AUTOSAR XML (schema 3.1.2)
package /Components/SWC_VSSp
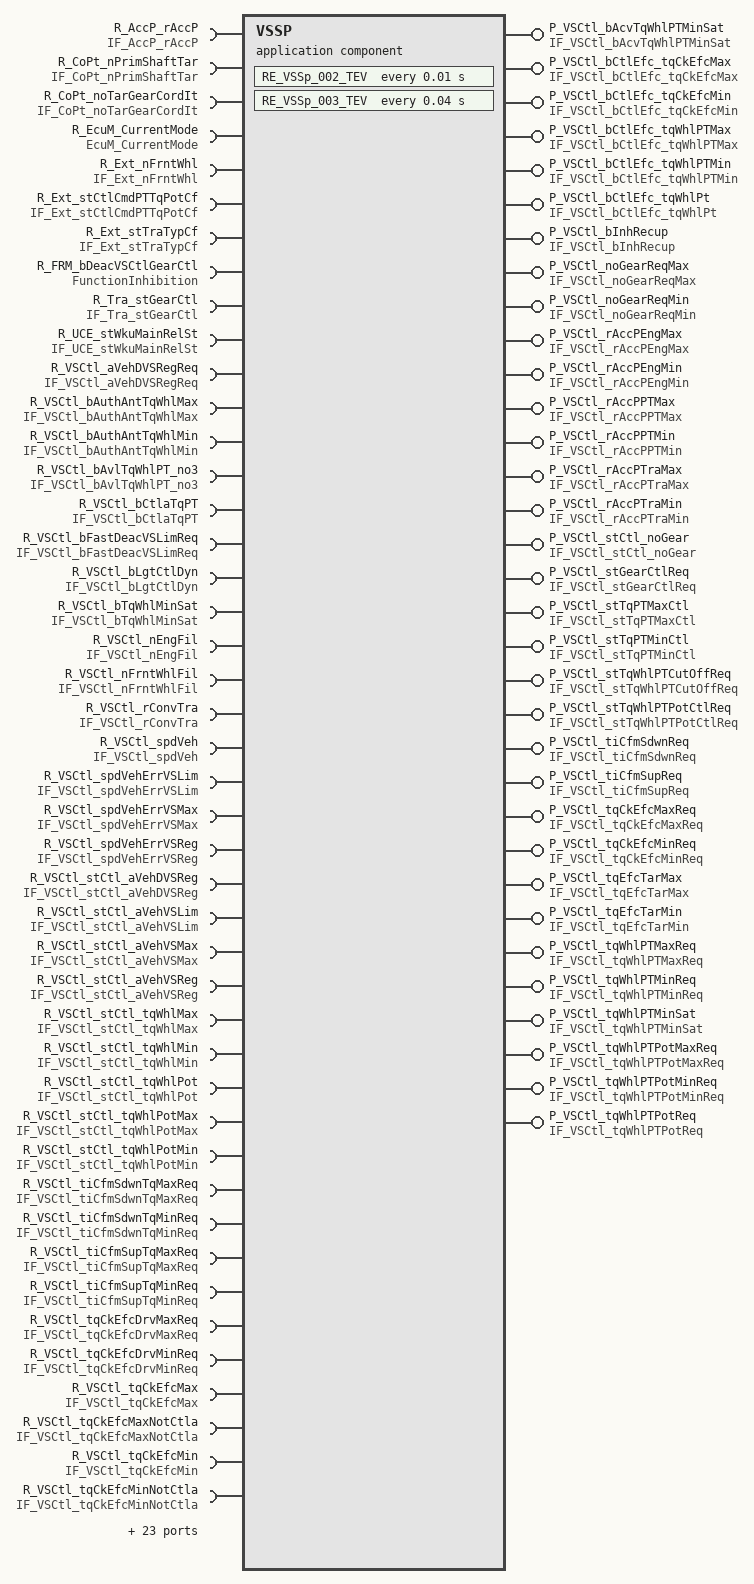
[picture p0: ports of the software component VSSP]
  application software component type VSSP  # VSSp
    33 x provide port:
      P_VSCtl_bAcvTqWhlPTMinSat: unqueued-sender-com-spec{data-element=VSCtl_bAcvTqWhlPTMinSat, can-invalidate=false, init-value=C_Boolean_False}, provided-interface=IF_VSCtl_bAcvTqWhlPTMinSat
      P_VSCtl_bCtlEfc_tqCkEfcMax: unqueued-sender-com-spec{data-element=VSCtl_bCtlEfc_tqCkEfcMax, can-invalidate=false, init-value=ConstantValue}, provided-interface=IF_VSCtl_bCtlEfc_tqCkEfcMax
      P_VSCtl_bCtlEfc_tqCkEfcMin: unqueued-sender-com-spec{data-element=VSCtl_bCtlEfc_tqCkEfcMin, can-invalidate=false, init-value=ConstantValue1}, provided-interface=IF_VSCtl_bCtlEfc_tqCkEfcMin
      P_VSCtl_bCtlEfc_tqWhlPTMax: unqueued-sender-com-spec{data-element=VSCtl_bCtlEfc_tqWhlPTMax, can-invalidate=false, init-value=ConstantValue3}, provided-interface=IF_VSCtl_bCtlEfc_tqWhlPTMax
      P_VSCtl_bCtlEfc_tqWhlPTMin: unqueued-sender-com-spec{data-element=VSCtl_bCtlEfc_tqWhlPTMin, can-invalidate=false, init-value=ConstantValue5}, provided-interface=IF_VSCtl_bCtlEfc_tqWhlPTMin
      P_VSCtl_bCtlEfc_tqWhlPt: unqueued-sender-com-spec{data-element=VSCtl_bCtlEfc_tqWhlPt, can-invalidate=false, init-value=C_Boolean_False7}, provided-interface=IF_VSCtl_bCtlEfc_tqWhlPt
      P_VSCtl_bInhRecup: unqueued-sender-com-spec{data-element=VSCtl_bInhRecup, can-invalidate=false, init-value=ConstantValue9}, provided-interface=IF_VSCtl_bInhRecup
      P_VSCtl_noGearReqMax: unqueued-sender-com-spec{data-element=VSCtl_noGearReqMax, can-invalidate=false, init-value=C_UInt8_15}, provided-interface=IF_VSCtl_noGearReqMax
      P_VSCtl_noGearReqMin: unqueued-sender-com-spec{data-element=VSCtl_noGearReqMin, can-invalidate=false, init-value=C_UInt8_0}, provided-interface=IF_VSCtl_noGearReqMin
      P_VSCtl_rAccPEngMax: unqueued-sender-com-spec{data-element=VSCtl_rAccPEngMax, can-invalidate=false, init-value=ConstantValue11}, provided-interface=IF_VSCtl_rAccPEngMax
      P_VSCtl_rAccPEngMin: unqueued-sender-com-spec{data-element=VSCtl_rAccPEngMin, can-invalidate=false, init-value=ConstantValue13}, provided-interface=IF_VSCtl_rAccPEngMin
      P_VSCtl_rAccPPTMax: unqueued-sender-com-spec{data-element=VSCtl_rAccPPTMax, can-invalidate=false, init-value=C_UInt16_12800}, provided-interface=IF_VSCtl_rAccPPTMax
      P_VSCtl_rAccPPTMin: unqueued-sender-com-spec{data-element=VSCtl_rAccPPTMin, can-invalidate=false, init-value=C_UInt16_0}, provided-interface=IF_VSCtl_rAccPPTMin
      P_VSCtl_rAccPTraMax: unqueued-sender-com-spec{data-element=VSCtl_rAccPTraMax, can-invalidate=false, init-value=ConstantValue15}, provided-interface=IF_VSCtl_rAccPTraMax
      P_VSCtl_rAccPTraMin: unqueued-sender-com-spec{data-element=VSCtl_rAccPTraMin, can-invalidate=false, init-value=ConstantValue17}, provided-interface=IF_VSCtl_rAccPTraMin
      P_VSCtl_stCtl_noGear: unqueued-sender-com-spec{data-element=VSCtl_stCtl_noGear, can-invalidate=false, init-value=ConstantValue19}, provided-interface=IF_VSCtl_stCtl_noGear
      P_VSCtl_stGearCtlReq: unqueued-sender-com-spec{data-element=VSCtl_stGearCtlReq, can-invalidate=false, init-value=C_UInt8_021}, provided-interface=IF_VSCtl_stGearCtlReq
      P_VSCtl_stTqPTMaxCtl: unqueued-sender-com-spec{data-element=VSCtl_stTqPTMaxCtl, can-invalidate=false, init-value=ConstantValue23}, provided-interface=IF_VSCtl_stTqPTMaxCtl
      P_VSCtl_stTqPTMinCtl: unqueued-sender-com-spec{data-element=VSCtl_stTqPTMinCtl, can-invalidate=false, init-value=ConstantValue25}, provided-interface=IF_VSCtl_stTqPTMinCtl
      P_VSCtl_stTqWhlPTCutOffReq: unqueued-sender-com-spec{data-element=VSCtl_stTqWhlPTCutOffReq, can-invalidate=false, init-value=ConstantValue27}, provided-interface=IF_VSCtl_stTqWhlPTCutOffReq
      P_VSCtl_stTqWhlPTPotCtlReq: unqueued-sender-com-spec{data-element=VSCtl_stTqWhlPTPotCtlReq, can-invalidate=false, init-value=C_UInt8_029}, provided-interface=IF_VSCtl_stTqWhlPTPotCtlReq
      P_VSCtl_tiCfmSdwnReq: unqueued-sender-com-spec{data-element=VSCtl_tiCfmSdwnReq, can-invalidate=false, init-value=C_UInt16_031}, provided-interface=IF_VSCtl_tiCfmSdwnReq
      P_VSCtl_tiCfmSupReq: unqueued-sender-com-spec{data-element=VSCtl_tiCfmSupReq, can-invalidate=false, init-value=C_UInt16_033}, provided-interface=IF_VSCtl_tiCfmSupReq
      P_VSCtl_tqCkEfcMaxReq: unqueued-sender-com-spec{data-element=VSCtl_tqCkEfcMaxReq, can-invalidate=false, init-value=ConstantValue35}, provided-interface=IF_VSCtl_tqCkEfcMaxReq
      P_VSCtl_tqCkEfcMinReq: unqueued-sender-com-spec{data-element=VSCtl_tqCkEfcMinReq, can-invalidate=false, init-value=ConstantValue37}, provided-interface=IF_VSCtl_tqCkEfcMinReq
      P_VSCtl_tqEfcTarMax: unqueued-sender-com-spec{data-element=VSCtl_tqEfcTarMax, can-invalidate=false, init-value=C_SInt16_32000}, provided-interface=IF_VSCtl_tqEfcTarMax
      P_VSCtl_tqEfcTarMin: unqueued-sender-com-spec{data-element=VSCtl_tqEfcTarMin, can-invalidate=false, init-value=C_SInt16_m32000}, provided-interface=IF_VSCtl_tqEfcTarMin
      P_VSCtl_tqWhlPTMaxReq: unqueued-sender-com-spec{data-element=VSCtl_tqWhlPTMaxReq, can-invalidate=false, init-value=C_SInt16_22000}, provided-interface=IF_VSCtl_tqWhlPTMaxReq
      P_VSCtl_tqWhlPTMinReq: unqueued-sender-com-spec{data-element=VSCtl_tqWhlPTMinReq, can-invalidate=false, init-value=C_SInt16_m8000}, provided-interface=IF_VSCtl_tqWhlPTMinReq
      P_VSCtl_tqWhlPTMinSat: unqueued-sender-com-spec{data-element=VSCtl_tqWhlPTMinSat, can-invalidate=false, init-value=C_SInt16_m800039}, provided-interface=IF_VSCtl_tqWhlPTMinSat
      P_VSCtl_tqWhlPTPotMaxReq: unqueued-sender-com-spec{data-element=VSCtl_tqWhlPTPotMaxReq, can-invalidate=false, init-value=C_SInt16_2200041}, provided-interface=IF_VSCtl_tqWhlPTPotMaxReq
      P_VSCtl_tqWhlPTPotMinReq: unqueued-sender-com-spec{data-element=VSCtl_tqWhlPTPotMinReq, can-invalidate=false, init-value=C_SInt16_m800043}, provided-interface=IF_VSCtl_tqWhlPTPotMinReq
      P_VSCtl_tqWhlPTPotReq: unqueued-sender-com-spec{data-element=VSCtl_tqWhlPTPotReq, can-invalidate=false, init-value=C_SInt16_m800045}, provided-interface=IF_VSCtl_tqWhlPTPotReq
    67 x require port:
      R_AccP_rAccP: unqueued-receiver-com-spec{data-element=AccP_rAccP, init-value=ConstantValue47, resync-time=0}, required-interface=IF_AccP_rAccP
      R_CoPt_nPrimShaftTar: unqueued-receiver-com-spec{data-element=CoPt_nPrimShaftTar, init-value=ConstantValue49, resync-time=0}, required-interface=IF_CoPt_nPrimShaftTar
      R_CoPt_noTarGearCordIt: unqueued-receiver-com-spec{data-element=CoPt_noTarGearCordIt, init-value=ConstantValue51, resync-time=0}, required-interface=IF_CoPt_noTarGearCordIt
      R_EcuM_CurrentMode: required-interface=EcuM_CurrentMode  # Requirement: 01552_09_00532-SSTG-C007(2)
      R_Ext_nFrntWhl: unqueued-receiver-com-spec{data-element=Ext_nFrntWhl, init-value=ConstantValue53, resync-time=0}, required-interface=IF_Ext_nFrntWhl
      R_Ext_stCtlCmdPTTqPotCf: unqueued-receiver-com-spec{data-element=Ext_stCtlCmdPTTqPotCf, init-value=ConstantValue55, resync-time=0}, required-interface=IF_Ext_stCtlCmdPTTqPotCf
      R_Ext_stTraTypCf: unqueued-receiver-com-spec{data-element=Ext_stTraTypCf, init-value=ConstantValue57, resync-time=0}, required-interface=IF_Ext_stTraTypCf
      R_FRM_bDeacVSCtlGearCtl: required-interface=FunctionInhibition
      R_Tra_stGearCtl: unqueued-receiver-com-spec{data-element=Tra_stGearCtl, init-value=C_UInt8_059, resync-time=0}, required-interface=IF_Tra_stGearCtl
      R_UCE_stWkuMainRelSt: required-interface=IF_UCE_stWkuMainRelSt  # Requirement: 01552_09_00532-SSTG-C011(1)
      R_VSCtl_aVehDVSRegReq: unqueued-receiver-com-spec{data-element=VSCtl_aVehDVSRegReq, init-value=ConstantValue61, resync-time=0}, required-interface=IF_VSCtl_aVehDVSRegReq
      R_VSCtl_bAuthAntTqWhlMax: unqueued-receiver-com-spec{data-element=VSCtl_bAuthAntTqWhlMax, init-value=ConstantValue63, resync-time=0}, required-interface=IF_VSCtl_bAuthAntTqWhlMax
      R_VSCtl_bAuthAntTqWhlMin: unqueued-receiver-com-spec{data-element=VSCtl_bAuthAntTqWhlMin, init-value=ConstantValue65, resync-time=0}, required-interface=IF_VSCtl_bAuthAntTqWhlMin
      R_VSCtl_bAvlTqWhlPT_no3: unqueued-receiver-com-spec{data-element=VSCtl_bAvlTqWhlPT_no3, init-value=ConstantValue67, resync-time=0}, required-interface=IF_VSCtl_bAvlTqWhlPT_no3
      R_VSCtl_bCtlaTqPT: unqueued-receiver-com-spec{data-element=VSCtl_bCtlaTqPT, init-value=ConstantValue69, resync-time=0}, required-interface=IF_VSCtl_bCtlaTqPT
      R_VSCtl_bFastDeacVSLimReq: unqueued-receiver-com-spec{data-element=VSCtl_bFastDeacVSLimReq, init-value=ConstantValue71, resync-time=0}, required-interface=IF_VSCtl_bFastDeacVSLimReq
      R_VSCtl_bLgtCtlDyn: unqueued-receiver-com-spec{data-element=VSCtl_bLgtCtlDyn, init-value=ConstantValue73, resync-time=0}, required-interface=IF_VSCtl_bLgtCtlDyn
      R_VSCtl_bTqWhlMinSat: unqueued-receiver-com-spec{data-element=VSCtl_bTqWhlMinSat, init-value=ConstantValue75, resync-time=0}, required-interface=IF_VSCtl_bTqWhlMinSat
      R_VSCtl_nEngFil: unqueued-receiver-com-spec{data-element=VSCtl_nEngFil, init-value=ConstantValue77, resync-time=0}, required-interface=IF_VSCtl_nEngFil
      R_VSCtl_nFrntWhlFil: unqueued-receiver-com-spec{data-element=VSCtl_nFrntWhlFil, init-value=ConstantValue79, resync-time=0}, required-interface=IF_VSCtl_nFrntWhlFil
      R_VSCtl_rConvTra: unqueued-receiver-com-spec{data-element=VSCtl_rConvTra, init-value=ConstantValue81, resync-time=0}, required-interface=IF_VSCtl_rConvTra
      R_VSCtl_spdVeh: unqueued-receiver-com-spec{data-element=VSCtl_spdVeh, init-value=ConstantValue83, resync-time=0}, required-interface=IF_VSCtl_spdVeh
      R_VSCtl_spdVehErrVSLim: unqueued-receiver-com-spec{data-element=VSCtl_spdVehErrVSLim, init-value=ConstantValue85, resync-time=0}, required-interface=IF_VSCtl_spdVehErrVSLim
      R_VSCtl_spdVehErrVSMax: unqueued-receiver-com-spec{data-element=VSCtl_spdVehErrVSMax, init-value=ConstantValue87, resync-time=0}, required-interface=IF_VSCtl_spdVehErrVSMax
      R_VSCtl_spdVehErrVSReg: unqueued-receiver-com-spec{data-element=VSCtl_spdVehErrVSReg, init-value=ConstantValue89, resync-time=0}, required-interface=IF_VSCtl_spdVehErrVSReg
      R_VSCtl_stCtl_aVehDVSReg: unqueued-receiver-com-spec{data-element=VSCtl_stCtl_aVehDVSReg, init-value=ConstantValue91, resync-time=0}, required-interface=IF_VSCtl_stCtl_aVehDVSReg
      R_VSCtl_stCtl_aVehVSLim: unqueued-receiver-com-spec{data-element=VSCtl_stCtl_aVehVSLim, init-value=ConstantValue93, resync-time=0}, required-interface=IF_VSCtl_stCtl_aVehVSLim
      R_VSCtl_stCtl_aVehVSMax: unqueued-receiver-com-spec{data-element=VSCtl_stCtl_aVehVSMax, init-value=ConstantValue95, resync-time=0}, required-interface=IF_VSCtl_stCtl_aVehVSMax
      R_VSCtl_stCtl_aVehVSReg: unqueued-receiver-com-spec{data-element=VSCtl_stCtl_aVehVSReg, init-value=ConstantValue97, resync-time=0}, required-interface=IF_VSCtl_stCtl_aVehVSReg
      R_VSCtl_stCtl_tqWhlMax: unqueued-receiver-com-spec{data-element=VSCtl_stCtl_tqWhlMax, init-value=ConstantValue99, resync-time=0}, required-interface=IF_VSCtl_stCtl_tqWhlMax
      R_VSCtl_stCtl_tqWhlMin: unqueued-receiver-com-spec{data-element=VSCtl_stCtl_tqWhlMin, init-value=ConstantValue101, resync-time=0}, required-interface=IF_VSCtl_stCtl_tqWhlMin
      R_VSCtl_stCtl_tqWhlPot: unqueued-receiver-com-spec{data-element=VSCtl_stCtl_tqWhlPot, init-value=ConstantValue103, resync-time=0}, required-interface=IF_VSCtl_stCtl_tqWhlPot
      R_VSCtl_stCtl_tqWhlPotMax: unqueued-receiver-com-spec{data-element=VSCtl_stCtl_tqWhlPotMax, init-value=ConstantValue105, resync-time=0}, required-interface=IF_VSCtl_stCtl_tqWhlPotMax
      R_VSCtl_stCtl_tqWhlPotMin: unqueued-receiver-com-spec{data-element=VSCtl_stCtl_tqWhlPotMin, init-value=ConstantValue107, resync-time=0}, required-interface=IF_VSCtl_stCtl_tqWhlPotMin
      R_VSCtl_tiCfmSdwnTqMaxReq: unqueued-receiver-com-spec{data-element=VSCtl_tiCfmSdwnTqMaxReq, init-value=ConstantValue109, resync-time=0}, required-interface=IF_VSCtl_tiCfmSdwnTqMaxReq
      R_VSCtl_tiCfmSdwnTqMinReq: unqueued-receiver-com-spec{data-element=VSCtl_tiCfmSdwnTqMinReq, init-value=ConstantValue111, resync-time=0}, required-interface=IF_VSCtl_tiCfmSdwnTqMinReq
      R_VSCtl_tiCfmSupTqMaxReq: unqueued-receiver-com-spec{data-element=VSCtl_tiCfmSupTqMaxReq, init-value=ConstantValue113, resync-time=0}, required-interface=IF_VSCtl_tiCfmSupTqMaxReq
      R_VSCtl_tiCfmSupTqMinReq: unqueued-receiver-com-spec{data-element=VSCtl_tiCfmSupTqMinReq, init-value=ConstantValue115, resync-time=0}, required-interface=IF_VSCtl_tiCfmSupTqMinReq
      R_VSCtl_tqCkEfcDrvMaxReq: unqueued-receiver-com-spec{data-element=VSCtl_tqCkEfcDrvMaxReq, init-value=ConstantValue117, resync-time=0}, required-interface=IF_VSCtl_tqCkEfcDrvMaxReq
      R_VSCtl_tqCkEfcDrvMinReq: unqueued-receiver-com-spec{data-element=VSCtl_tqCkEfcDrvMinReq, init-value=ConstantValue119, resync-time=0}, required-interface=IF_VSCtl_tqCkEfcDrvMinReq
      R_VSCtl_tqCkEfcMax: unqueued-receiver-com-spec{data-element=VSCtl_tqCkEfcMax, init-value=ConstantValue121, resync-time=0}, required-interface=IF_VSCtl_tqCkEfcMax
      R_VSCtl_tqCkEfcMaxNotCtla: unqueued-receiver-com-spec{data-element=VSCtl_tqCkEfcMaxNotCtla, init-value=ConstantValue123, resync-time=0}, required-interface=IF_VSCtl_tqCkEfcMaxNotCtla
      R_VSCtl_tqCkEfcMin: unqueued-receiver-com-spec{data-element=VSCtl_tqCkEfcMin, init-value=ConstantValue125, resync-time=0}, required-interface=IF_VSCtl_tqCkEfcMin
      R_VSCtl_tqCkEfcMinNotCtla: unqueued-receiver-com-spec{data-element=VSCtl_tqCkEfcMinNotCtla, init-value=ConstantValue127, resync-time=0}, required-interface=IF_VSCtl_tqCkEfcMinNotCtla
      R_VSCtl_tqCkEfcPreCoVSCMinReq: unqueued-receiver-com-spec{data-element=VSCtl_tqCkEfcPreCoVSCMinReq, init-value=ConstantValue129, resync-time=0}, required-interface=IF_VSCtl_tqCkEfcPreCoVSCMinReq
      R_VSCtl_tqCkEfcPreCoVSCtlReq: unqueued-receiver-com-spec{data-element=VSCtl_tqCkEfcPreCoVSCtlReq, init-value=ConstantValue131, resync-time=0}, required-interface=IF_VSCtl_tqCkEfcPreCoVSCtlReq
      R_VSCtl_tqLossTra: unqueued-receiver-com-spec{data-element=VSCtl_tqLossTra, init-value=ConstantValue133, resync-time=0}, required-interface=IF_VSCtl_tqLossTra
      R_VSCtl_tqWhlMaxReq: unqueued-receiver-com-spec{data-element=VSCtl_tqWhlMaxReq, init-value=ConstantValue135, resync-time=0}, required-interface=IF_VSCtl_tqWhlMaxReq
      R_VSCtl_tqWhlMinReq: unqueued-receiver-com-spec{data-element=VSCtl_tqWhlMinReq, init-value=ConstantValue137, resync-time=0}, required-interface=IF_VSCtl_tqWhlMinReq
      R_VSCtl_tqWhlMinSat: unqueued-receiver-com-spec{data-element=VSCtl_tqWhlMinSat, init-value=ConstantValue139, resync-time=0}, required-interface=IF_VSCtl_tqWhlMinSat
      R_VSCtl_tqWhlPTDrvMaxReq: unqueued-receiver-com-spec{data-element=VSCtl_tqWhlPTDrvMaxReq, init-value=ConstantValue141, resync-time=0}, required-interface=IF_VSCtl_tqWhlPTDrvMaxReq
      R_VSCtl_tqWhlPTDrvMinReq: unqueued-receiver-com-spec{data-element=VSCtl_tqWhlPTDrvMinReq, init-value=ConstantValue143, resync-time=0}, required-interface=IF_VSCtl_tqWhlPTDrvMinReq
      R_VSCtl_tqWhlPTDrvMinReqRaw: unqueued-receiver-com-spec{data-element=VSCtl_tqWhlPTDrvMinReqRaw, init-value=ConstantValue145, resync-time=0}, required-interface=IF_VSCtl_tqWhlPTDrvMinReqRaw
      R_VSCtl_tqWhlPTMax: unqueued-receiver-com-spec{data-element=VSCtl_tqWhlPTMax, init-value=ConstantValue147, resync-time=0}, required-interface=IF_VSCtl_tqWhlPTMax
      R_VSCtl_tqWhlPTMaxNotCtla: unqueued-receiver-com-spec{data-element=VSCtl_tqWhlPTMaxNotCtla, init-value=ConstantValue149, resync-time=0}, required-interface=IF_VSCtl_tqWhlPTMaxNotCtla
      R_VSCtl_tqWhlPTMin: unqueued-receiver-com-spec{data-element=VSCtl_tqWhlPTMin, init-value=ConstantValue151, resync-time=0}, required-interface=IF_VSCtl_tqWhlPTMin
      R_VSCtl_tqWhlPTMinNotCtla: unqueued-receiver-com-spec{data-element=VSCtl_tqWhlPTMinNotCtla, init-value=ConstantValue153, resync-time=0}, required-interface=IF_VSCtl_tqWhlPTMinNotCtla
      R_VSCtl_tqWhlPTPotRawMax: unqueued-receiver-com-spec{data-element=VSCtl_tqWhlPTPotRawMax, init-value=ConstantValue155, resync-time=0}, required-interface=IF_VSCtl_tqWhlPTPotRawMax
      R_VSCtl_tqWhlPTPotRawMin: unqueued-receiver-com-spec{data-element=VSCtl_tqWhlPTPotRawMin, init-value=ConstantValue157, resync-time=0}, required-interface=IF_VSCtl_tqWhlPTPotRawMin
      R_VSCtl_tqWhlPTPreCoVSCMaxReq: unqueued-receiver-com-spec{data-element=VSCtl_tqWhlPTPreCoVSCMaxReq, init-value=ConstantValue159, resync-time=0}, required-interface=IF_VSCtl_tqWhlPTPreCoVSCMaxReq
      R_VSCtl_tqWhlPTPreCoVSCMinReq: unqueued-receiver-com-spec{data-element=VSCtl_tqWhlPTPreCoVSCMinReq, init-value=ConstantValue161, resync-time=0}, required-interface=IF_VSCtl_tqWhlPTPreCoVSCMinReq
      R_VSCtl_tqWhlPTPreCoVSCtlReq: unqueued-receiver-com-spec{data-element=VSCtl_tqWhlPTPreCoVSCtlReq, init-value=ConstantValue163, resync-time=0}, required-interface=IF_VSCtl_tqWhlPTPreCoVSCtlReq
      R_VSCtl_tqWhlPotMaxReq: unqueued-receiver-com-spec{data-element=VSCtl_tqWhlPotMaxReq, init-value=ConstantValue165, resync-time=0}, required-interface=IF_VSCtl_tqWhlPotMaxReq
      R_VSCtl_tqWhlPotMinReq: unqueued-receiver-com-spec{data-element=VSCtl_tqWhlPotMinReq, init-value=ConstantValue167, resync-time=0}, required-interface=IF_VSCtl_tqWhlPotMinReq
      R_VSCtl_tqWhlPotReq: unqueued-receiver-com-spec{data-element=VSCtl_tqWhlPotReq, init-value=ConstantValue169, resync-time=0}, required-interface=IF_VSCtl_tqWhlPotReq
      R_VSSp_GetTimer_1ms_U32: required-interface=IF_CS_FRunTime_1MS_U32
      R_Ext_bCtlCmdPTTqCf: unqueued-receiver-com-spec{data-element=Ext_bCtlCmdPTTqCf, init-value=ConstantValue171, resync-time=0}, required-interface=IF_Ext_bCtlCmdPTTqCf  # R_Ext_bVSMaxpCf
  102 x constant specification:
    C_Boolean_False
      value:
        boolean literal C_Boolean_False: type=DT_VSCtl_bAcvTqWhlPTMinSat, value=false
    C_Boolean_False173
      value:
        boolean literal C_Boolean_False173: type=DT_VSCtl_bCtlEfc_tqWhlPT_pt1, value=false
    C_Boolean_False175
      value:
        boolean literal C_Boolean_False175: type=DT_VSCtl_bCtlEfc_tqWhlPT_pt2, value=false
    C_Boolean_False7
      value:
        boolean literal C_Boolean_False7: type=DT_VSCtl_bCtlEfc_tqWhlPt, value=false
    C_SInt16_22000
      value:
        integer literal C_SInt16_22000: type=DT_VSCtl_tqWhlPTMaxReq, value=22000
    C_SInt16_2200041
      value:
        integer literal C_SInt16_2200041: type=DT_VSCtl_tqWhlPTPotMaxReq, value=22000
    C_SInt16_32000
      value:
        integer literal C_SInt16_32000: type=DT_VSCtl_tqEfcTarMax, value=32000
    C_SInt16_m32000
      value:
        integer literal C_SInt16_m32000: type=DT_VSCtl_tqEfcTarMin, value=-32000
    C_SInt16_m8000
      value:
        integer literal C_SInt16_m8000: type=DT_VSCtl_tqWhlPTMinReq, value=-8000
    C_SInt16_m800039
      value:
        integer literal C_SInt16_m800039: type=DT_VSCtl_tqWhlPTMinSat, value=-8000
    C_SInt16_m800043
      value:
        integer literal C_SInt16_m800043: type=DT_VSCtl_tqWhlPTPotMinReq, value=-8000
    C_SInt16_m800045
      value:
        integer literal C_SInt16_m800045: type=DT_VSCtl_tqWhlPTPotReq, value=-8000
    C_UInt16_0
      value:
        integer literal C_UInt16_0: type=DT_VSCtl_rAccPPTMin, value=0
    C_UInt16_031
      value:
        integer literal C_UInt16_031: type=DT_VSCtl_tiCfmSdwnReq, value=0
    C_UInt16_033
      value:
        integer literal C_UInt16_033: type=DT_VSCtl_tiCfmSupReq, value=0
    C_UInt16_12800
      value:
        integer literal C_UInt16_12800: type=DT_VSCtl_rAccPPTMax, value=12800
    C_UInt8_0
      value:
        integer literal C_UInt8_0: type=DT_VSCtl_noGearReqMin, value=0
    C_UInt8_0177
      value:
        integer literal C_UInt8_0177: type=DT_VSCtl_stTqPTMaxCtl_pt2, value=0
    C_UInt8_0179
      value:
        integer literal C_UInt8_0179: type=DT_VSCtl_stTqPTMaxCtl_pt1, value=0
    C_UInt8_0181
      value:
        integer literal C_UInt8_0181: type=DT_VSCtl_stTqPTMinCtl_pt2, value=0
    C_UInt8_0183
      value:
        integer literal C_UInt8_0183: type=DT_VSCtl_stTqPTMinCtl_pt1, value=0
    C_UInt8_021
      value:
        integer literal C_UInt8_021: type=DT_VSCtl_stGearCtlReq, value=0
    C_UInt8_029
      value:
        integer literal C_UInt8_029: type=DT_VSCtl_stTqWhlPTPotCtlReq, value=0
    C_UInt8_059
      value:
        integer literal C_UInt8_059: type=DT_Tra_stGearCtl, value=0
    C_UInt8_15
      value:
        integer literal C_UInt8_15: type=DT_VSCtl_noGearReqMax, value=15
    ConstantValue
      value:
        boolean literal ConstantValue: type=DT_VSCtl_bCtlEfc_tqCkEfcMax, value=false
    ConstantValue1
      value:
        boolean literal ConstantValue1: type=DT_VSCtl_bCtlEfc_tqCkEfcMin, value=false
    ConstantValue101
      value:
        boolean literal ConstantValue101: type=DT_VSCtl_stCtl_tqWhlMin, value=false
    ConstantValue103
      value:
        boolean literal ConstantValue103: type=DT_VSCtl_stCtl_tqWhlPot, value=false
    ConstantValue105
      value:
        integer literal ConstantValue105: type=DT_VSCtl_stCtl_tqWhlPotMax, value=0
    ConstantValue107
      value:
        integer literal ConstantValue107: type=DT_VSCtl_stCtl_tqWhlPotMin, value=0
    ConstantValue109
      value:
        integer literal ConstantValue109: type=DT_VSCtl_tiCfmSdwnTqMaxReq, value=0
    ConstantValue11
      value:
        integer literal ConstantValue11: type=DT_VSCtl_rAccPEngMax, value=12800
    ConstantValue111
      value:
        integer literal ConstantValue111: type=DT_VSCtl_tiCfmSdwnTqMinReq, value=0
    ConstantValue113
      value:
        integer literal ConstantValue113: type=DT_VSCtl_tiCfmSupTqMaxReq, value=0
    ConstantValue115
      value:
        integer literal ConstantValue115: type=DT_VSCtl_tiCfmSupTqMinReq, value=0
    ConstantValue117
      value:
        integer literal ConstantValue117: type=DT_VSCtl_tqCkEfcDrvMaxReq, value=32000
    ConstantValue119
      value:
        integer literal ConstantValue119: type=DT_VSCtl_tqCkEfcDrvMinReq, value=-32000
    ConstantValue121
      value:
        integer literal ConstantValue121: type=DT_VSCtl_tqCkEfcMax, value=32000
    ConstantValue123
      value:
        integer literal ConstantValue123: type=DT_VSCtl_tqCkEfcMaxNotCtla, value=0
    ConstantValue125
      value:
        integer literal ConstantValue125: type=DT_VSCtl_tqCkEfcMin, value=-32000
    ConstantValue127
      value:
        integer literal ConstantValue127: type=DT_VSCtl_tqCkEfcMinNotCtla, value=0
    ConstantValue129
      value:
        integer literal ConstantValue129: type=DT_VSCtl_tqCkEfcPreCoVSCMinReq, value=-32000
    ConstantValue13
      value:
        integer literal ConstantValue13: type=DT_VSCtl_rAccPEngMin, value=0
    ConstantValue131
      value:
        integer literal ConstantValue131: type=DT_VSCtl_tqCkEfcPreCoVSCtlReq, value=4000
    ConstantValue133
      value:
        integer literal ConstantValue133: type=DT_VSCtl_tqLossTra, value=0
    ConstantValue135
      value:
        integer literal ConstantValue135: type=DT_VSCtl_tqWhlMaxReq, value=32000
    ConstantValue137
      value:
        integer literal ConstantValue137: type=DT_VSCtl_tqWhlMinReq, value=-32000
    ConstantValue139
      value:
        integer literal ConstantValue139: type=DT_VSCtl_tqWhlMinSat, value=-32000
    ConstantValue141
      value:
        integer literal ConstantValue141: type=DT_VSCtl_tqWhlPTDrvMaxReq, value=32000
    ConstantValue143
      value:
        integer literal ConstantValue143: type=DT_VSCtl_tqWhlPTDrvMinReq, value=0
    ConstantValue145
      value:
        integer literal ConstantValue145: type=DT_VSCtl_tqWhlPTDrvMinReqRaw, value=0
    ConstantValue147
      value:
        integer literal ConstantValue147: type=DT_VSCtl_tqWhlPTMax, value=0
    ConstantValue149
      value:
        integer literal ConstantValue149: type=DT_VSCtl_tqWhlPTMaxNotCtla, value=0
    ConstantValue15
      value:
        integer literal ConstantValue15: type=DT_VSCtl_rAccPTraMax, value=0
    ConstantValue151
      value:
        integer literal ConstantValue151: type=DT_VSCtl_tqWhlPTMin, value=0
    ConstantValue153
      value:
        integer literal ConstantValue153: type=DT_VSCtl_tqWhlPTMinNotCtla, value=0
    ConstantValue155
      value:
        integer literal ConstantValue155: type=DT_VSCtl_tqWhlPTPotRawMax, value=-32000
    ConstantValue157
      value:
        integer literal ConstantValue157: type=DT_VSCtl_tqWhlPTPotRawMin, value=-32000
    ConstantValue159
      value:
        integer literal ConstantValue159: type=DT_VSCtl_tqWhlPTPreCoVSCMaxReq, value=-32000
    ConstantValue161
      value:
        integer literal ConstantValue161: type=DT_VSCtl_tqWhlPTPreCoVSCMinReq, value=-32000
    ConstantValue163
      value:
        integer literal ConstantValue163: type=DT_VSCtl_tqWhlPTPreCoVSCtlReq, value=0
    ConstantValue165
      value:
        integer literal ConstantValue165: type=DT_VSCtl_tqWhlPotMaxReq, value=32000
    ConstantValue167
      value:
        integer literal ConstantValue167: type=DT_VSCtl_tqWhlPotMinReq, value=-32000
    ConstantValue169
      value:
        integer literal ConstantValue169: type=DT_VSCtl_tqWhlPotReq, value=-32000
    ConstantValue17
      value:
        integer literal ConstantValue17: type=DT_VSCtl_rAccPTraMin, value=0
    ConstantValue171
      value:
        boolean literal ConstantValue171: type=DT_Ext_bCtlCmdPTTqCf, value=false
    ConstantValue19
      value:
        integer literal ConstantValue19: type=DT_VSCtl_stCtl_noGear, value=0
    ConstantValue23
      value:
        integer literal ConstantValue23: type=DT_VSCtl_stTqPTMaxCtl, value=0
    ConstantValue25
      value:
        integer literal ConstantValue25: type=DT_VSCtl_stTqPTMinCtl, value=0
    ConstantValue27
      value:
        integer literal ConstantValue27: type=DT_VSCtl_stTqWhlPTCutOffReq, value=0
    ConstantValue3
      value:
        boolean literal ConstantValue3: type=DT_VSCtl_bCtlEfc_tqWhlPTMax, value=false
    ConstantValue35
      value:
        integer literal ConstantValue35: type=DT_VSCtl_tqCkEfcMaxReq, value=32000
    ConstantValue37
      value:
        integer literal ConstantValue37: type=DT_VSCtl_tqCkEfcMinReq, value=-32000
    ConstantValue47
      value:
        integer literal ConstantValue47: type=DT_AccP_rAccP, value=0
    ConstantValue49
      value:
        integer literal ConstantValue49: type=DT_CoPt_nPrimShaftTar, value=0
    ConstantValue5
      value:
        boolean literal ConstantValue5: type=DT_VSCtl_bCtlEfc_tqWhlPTMin, value=false
    ConstantValue51
      value:
        integer literal ConstantValue51: type=DT_CoPt_noTarGearCordIt, value=0
    ConstantValue53
      value:
        integer literal ConstantValue53: type=DT_Ext_nFrntWhl, value=0
    ConstantValue55
      value:
        integer literal ConstantValue55: type=DT_Ext_stCtlCmdPTTqPotCf, value=0
    ConstantValue57
      value:
        integer literal ConstantValue57: type=DT_Ext_stTraTypCf, value=0
    ConstantValue61
      value:
        integer literal ConstantValue61: type=DT_VSCtl_aVehDVSRegReq, value=-10240
    ConstantValue63
      value:
        boolean literal ConstantValue63: type=DT_VSCtl_bAuthAntTqWhlMax, value=false
    ConstantValue65
      value:
        boolean literal ConstantValue65: type=DT_VSCtl_bAuthAntTqWhlMin, value=false
    ConstantValue67
      value:
        boolean literal ConstantValue67: type=DT_VSCtl_bAvlTqWhlPT_no3, value=false
    ConstantValue69
      value:
        boolean literal ConstantValue69: type=DT_VSCtl_bCtlaTqPT, value=false
    ConstantValue71
      value:
        boolean literal ConstantValue71: type=DT_VSCtl_bFastDeacVSLimReq, value=false
    ConstantValue73
      value:
        boolean literal ConstantValue73: type=DT_VSCtl_bLgtCtlDyn, value=false
    ConstantValue75
      value:
        boolean literal ConstantValue75: type=DT_VSCtl_bTqWhlMinSat, value=false
    ConstantValue77
      value:
        integer literal ConstantValue77: type=DT_VSCtl_nEngFil, value=0
    ConstantValue79
      value:
        integer literal ConstantValue79: type=DT_VSCtl_nFrntWhlFil, value=0
    ConstantValue81
      value:
        integer literal ConstantValue81: type=DT_VSCtl_rConvTra, value=2560
    ConstantValue83
      value:
        integer literal ConstantValue83: type=DT_VSCtl_spdVeh, value=0
    ConstantValue85
      value:
        integer literal ConstantValue85: type=DT_VSCtl_spdVehErrVSLim, value=0
    ConstantValue87
      value:
        integer literal ConstantValue87: type=DT_VSCtl_spdVehErrVSMax, value=0
    ConstantValue89
      value:
        integer literal ConstantValue89: type=DT_VSCtl_spdVehErrVSReg, value=0
    ConstantValue9
      value:
        boolean literal ConstantValue9: type=DT_VSCtl_bInhRecup, value=false
    ConstantValue91
      value:
        boolean literal ConstantValue91: type=DT_VSCtl_stCtl_aVehDVSReg, value=false
    ConstantValue93
      value:
        integer literal ConstantValue93: type=DT_VSCtl_stCtl_aVehVSLim, value=0
    ConstantValue95
      value:
        integer literal ConstantValue95: type=DT_VSCtl_stCtl_aVehVSMax, value=0
    ConstantValue97
      value:
        integer literal ConstantValue97: type=DT_VSCtl_stCtl_aVehVSReg, value=0
    ConstantValue99
      value:
        boolean literal ConstantValue99: type=DT_VSCtl_stCtl_tqWhlMax, value=false
  internal behavior IB_VSSp: component=VSSP
    mode switch event EV_VSSp_004_MSE: start-on-event=RE_VSSp_004_MSE, activation=ENTRY, mode=R_EcuM_CurrentMode.currentMode.RUN
    mode switch event EV_VSSp_001_MSE: start-on-event=RE_VSSp_001_MSE, activation=ENTRY, mode=R_EcuM_CurrentMode.currentMode.RUN
    timing event EV_VSSp_002_TEV: mode-dependency=dependent-on-mode=[R_UCE_stWkuMainRelSt.RCD_stWkuMainRelSt.Invalid, R_UCE_stWkuMainRelSt.RCD_stWkuMainRelSt.PostMainWakeUp, R_UCE_stWkuMainRelSt.RCD_stWkuMainRelSt.PreMainWakeUp], start-on-event=RE_VSSp_002_TEV, period=0.01
    timing event EV_VSSp_003_TEV: mode-dependency=dependent-on-mode=[R_UCE_stWkuMainRelSt.RCD_stWkuMainRelSt.Invalid, R_UCE_stWkuMainRelSt.RCD_stWkuMainRelSt.PostMainWakeUp, R_UCE_stWkuMainRelSt.RCD_stWkuMainRelSt.PreMainWakeUp], start-on-event=RE_VSSp_003_TEV, period=0.04
    6 x inter runnable variable, all with sw-calibration-access=READ-WRITE, communication-approach=EXPLICIT:
      VSCtl_bCtlEfc_tqWhlPT_pt2: type=DT_VSCtl_bCtlEfc_tqWhlPT_pt2, init-value=C_Boolean_False175
      VSCtl_stTqPTMaxCtl_pt2: type=DT_VSCtl_stTqPTMaxCtl_pt2, init-value=C_UInt8_0177
      VSCtl_bCtlEfc_tqWhlPT_pt1: type=DT_VSCtl_bCtlEfc_tqWhlPT_pt1, init-value=C_Boolean_False173
      VSCtl_stTqPTMinCtl_pt1: type=DT_VSCtl_stTqPTMinCtl_pt1, init-value=C_UInt8_0183
      VSCtl_stTqPTMinCtl_pt2: type=DT_VSCtl_stTqPTMinCtl_pt2, init-value=C_UInt8_0181
      VSCtl_stTqPTMaxCtl_pt1: type=DT_VSCtl_stTqPTMaxCtl_pt1, init-value=C_UInt8_0179
    4 x runnable:
      RE_VSSp_002_TEV: written-variable=[VSCtl_bCtlEfc_tqWhlPT_pt1, VSCtl_bCtlEfc_tqWhlPT_pt2, VSCtl_stTqPTMinCtl_pt1, VSCtl_stTqPTMinCtl_pt2, VSCtl_stTqPTMaxCtl_pt1, VSCtl_stTqPTMaxCtl_pt2]  # RE_01552_10_02851_10ms
        63 x data receive point:
          dr_VSCtl_tqWhlPTMin: data-element=R_VSCtl_tqWhlPTMin.VSCtl_tqWhlPTMin
          dr_VSCtl_tqCkEfcMin: data-element=R_VSCtl_tqCkEfcMin.VSCtl_tqCkEfcMin
          dr_VSCtl_tqWhlPTPotRawMax: data-element=R_VSCtl_tqWhlPTPotRawMax.VSCtl_tqWhlPTPotRawMax
          dr_VSCtl_tqWhlPTPreCoVSCMaxReq: data-element=R_VSCtl_tqWhlPTPreCoVSCMaxReq.VSCtl_tqWhlPTPreCoVSCMaxReq
          dr_VSCtl_bCtlaTqPT: data-element=R_VSCtl_bCtlaTqPT.VSCtl_bCtlaTqPT
          dr_VSCtl_spdVehErrVSMax: data-element=R_VSCtl_spdVehErrVSMax.VSCtl_spdVehErrVSMax
          dr_VSCtl_tqWhlPTDrvMinReqRaw: data-element=R_VSCtl_tqWhlPTDrvMinReqRaw.VSCtl_tqWhlPTDrvMinReqRaw
          dr_VSCtl_rConvTra: data-element=R_VSCtl_rConvTra.VSCtl_rConvTra
          dr_VSCtl_aVehDVSRegReq: data-element=R_VSCtl_aVehDVSRegReq.VSCtl_aVehDVSRegReq
          dr_VSCtl_tqCkEfcMax: data-element=R_VSCtl_tqCkEfcMax.VSCtl_tqCkEfcMax
          dr_VSCtl_stCtl_tqWhlMin: data-element=R_VSCtl_stCtl_tqWhlMin.VSCtl_stCtl_tqWhlMin
          dr_AccP_rAccP: data-element=R_AccP_rAccP.AccP_rAccP
          dr_VSCtl_tqCkEfcDrvMaxReq: data-element=R_VSCtl_tqCkEfcDrvMaxReq.VSCtl_tqCkEfcDrvMaxReq
          dr_Ext_nFrntWhl: data-element=R_Ext_nFrntWhl.Ext_nFrntWhl
          dr_CoPt_nPrimShaftTar: data-element=R_CoPt_nPrimShaftTar.CoPt_nPrimShaftTar
          dr_VSCtl_tqWhlMaxReq: data-element=R_VSCtl_tqWhlMaxReq.VSCtl_tqWhlMaxReq
          dr_VSCtl_tqCkEfcPreCoVSCtlReq: data-element=R_VSCtl_tqCkEfcPreCoVSCtlReq.VSCtl_tqCkEfcPreCoVSCtlReq
          dr_Ext_stCtlCmdPTTqPotCf: data-element=R_Ext_stCtlCmdPTTqPotCf.Ext_stCtlCmdPTTqPotCf
          dr_VSCtl_tqWhlMinReq: data-element=R_VSCtl_tqWhlMinReq.VSCtl_tqWhlMinReq
          dr_Ext_stTraTypCf: data-element=R_Ext_stTraTypCf.Ext_stTraTypCf
          dr_VSCtl_tqCkEfcDrvMinReq: data-element=R_VSCtl_tqCkEfcDrvMinReq.VSCtl_tqCkEfcDrvMinReq
          dr_VSCtl_tqCkEfcMinNotCtla: data-element=R_VSCtl_tqCkEfcMinNotCtla.VSCtl_tqCkEfcMinNotCtla
          dr_VSCtl_bLgtCtlDyn: data-element=R_VSCtl_bLgtCtlDyn.VSCtl_bLgtCtlDyn
          dr_VSCtl_tqWhlPTPreCoVSCMinReq: data-element=R_VSCtl_tqWhlPTPreCoVSCMinReq.VSCtl_tqWhlPTPreCoVSCMinReq
          dr_VSCtl_nFrntWhlFil: data-element=R_VSCtl_nFrntWhlFil.VSCtl_nFrntWhlFil
          dr_VSCtl_tqWhlPTPreCoVSCtlReq: data-element=R_VSCtl_tqWhlPTPreCoVSCtlReq.VSCtl_tqWhlPTPreCoVSCtlReq
          dr_VSCtl_bAuthAntTqWhlMin: data-element=R_VSCtl_bAuthAntTqWhlMin.VSCtl_bAuthAntTqWhlMin
          dr_VSCtl_spdVeh: data-element=R_VSCtl_spdVeh.VSCtl_spdVeh
          dr_VSCtl_tqCkEfcPreCoVSCMinReq: data-element=R_VSCtl_tqCkEfcPreCoVSCMinReq.VSCtl_tqCkEfcPreCoVSCMinReq
          dr_VSCtl_tiCfmSdwnTqMinReq: data-element=R_VSCtl_tiCfmSdwnTqMinReq.VSCtl_tiCfmSdwnTqMinReq
          dr_VSCtl_bFastDeacVSLimReq: data-element=R_VSCtl_bFastDeacVSLimReq.VSCtl_bFastDeacVSLimReq
          dr_VSCtl_bAuthAntTqWhlMax: data-element=R_VSCtl_bAuthAntTqWhlMax.VSCtl_bAuthAntTqWhlMax
          dr_VSCtl_tqWhlPTPotRawMin: data-element=R_VSCtl_tqWhlPTPotRawMin.VSCtl_tqWhlPTPotRawMin
          dr_VSCtl_stCtl_aVehVSReg: data-element=R_VSCtl_stCtl_aVehVSReg.VSCtl_stCtl_aVehVSReg
          dr_VSCtl_stCtl_tqWhlPotMax: data-element=R_VSCtl_stCtl_tqWhlPotMax.VSCtl_stCtl_tqWhlPotMax
          dr_VSCtl_nEngFil: data-element=R_VSCtl_nEngFil.VSCtl_nEngFil
          dr_Tra_stGearCtl: data-element=R_Tra_stGearCtl.Tra_stGearCtl
          dr_VSCtl_tiCfmSdwnTqMaxReq: data-element=R_VSCtl_tiCfmSdwnTqMaxReq.VSCtl_tiCfmSdwnTqMaxReq
          dr_VSCtl_tqWhlPTMinNotCtla: data-element=R_VSCtl_tqWhlPTMinNotCtla.VSCtl_tqWhlPTMinNotCtla
          dr_VSCtl_stCtl_aVehVSLim: data-element=R_VSCtl_stCtl_aVehVSLim.VSCtl_stCtl_aVehVSLim
          dr_VSCtl_bTqWhlMinSat: data-element=R_VSCtl_bTqWhlMinSat.VSCtl_bTqWhlMinSat
          dr_VSCtl_tiCfmSupTqMinReq: data-element=R_VSCtl_tiCfmSupTqMinReq.VSCtl_tiCfmSupTqMinReq
          dr_VSCtl_stCtl_tqWhlMax: data-element=R_VSCtl_stCtl_tqWhlMax.VSCtl_stCtl_tqWhlMax
          dr_VSCtl_tqLossTra: data-element=R_VSCtl_tqLossTra.VSCtl_tqLossTra
          DRP_R_Ext_bCtlCmdPTTqCf_Ext_bCtlCmdPTTqCf: data-element=R_Ext_bCtlCmdPTTqCf.Ext_bCtlCmdPTTqCf
          dr_VSCtl_spdVehErrVSLim: data-element=R_VSCtl_spdVehErrVSLim.VSCtl_spdVehErrVSLim
          dr_VSCtl_stCtl_aVehDVSReg: data-element=R_VSCtl_stCtl_aVehDVSReg.VSCtl_stCtl_aVehDVSReg
          dr_VSCtl_bAvlTqWhlPT_no3: data-element=R_VSCtl_bAvlTqWhlPT_no3.VSCtl_bAvlTqWhlPT_no3
          dr_VSCtl_stCtl_tqWhlPot: data-element=R_VSCtl_stCtl_tqWhlPot.VSCtl_stCtl_tqWhlPot
          dr_VSCtl_tqWhlPotMaxReq: data-element=R_VSCtl_tqWhlPotMaxReq.VSCtl_tqWhlPotMaxReq
          dr_CoPt_noTarGearCordIt: data-element=R_CoPt_noTarGearCordIt.CoPt_noTarGearCordIt
          dr_VSCtl_tiCfmSupTqMaxReq: data-element=R_VSCtl_tiCfmSupTqMaxReq.VSCtl_tiCfmSupTqMaxReq
          dr_VSCtl_tqWhlPotReq: data-element=R_VSCtl_tqWhlPotReq.VSCtl_tqWhlPotReq
          dr_VSCtl_tqWhlPTDrvMinReq: data-element=R_VSCtl_tqWhlPTDrvMinReq.VSCtl_tqWhlPTDrvMinReq
          dr_VSCtl_tqWhlPTMaxNotCtla: data-element=R_VSCtl_tqWhlPTMaxNotCtla.VSCtl_tqWhlPTMaxNotCtla
          dr_VSCtl_tqWhlPTDrvMaxReq: data-element=R_VSCtl_tqWhlPTDrvMaxReq.VSCtl_tqWhlPTDrvMaxReq
          dr_VSCtl_tqWhlPTMax: data-element=R_VSCtl_tqWhlPTMax.VSCtl_tqWhlPTMax
          dr_VSCtl_tqWhlPotMinReq: data-element=R_VSCtl_tqWhlPotMinReq.VSCtl_tqWhlPotMinReq
          dr_VSCtl_spdVehErrVSReg: data-element=R_VSCtl_spdVehErrVSReg.VSCtl_spdVehErrVSReg
          dr_VSCtl_stCtl_aVehVSMax: data-element=R_VSCtl_stCtl_aVehVSMax.VSCtl_stCtl_aVehVSMax
          dr_VSCtl_tqCkEfcMaxNotCtla: data-element=R_VSCtl_tqCkEfcMaxNotCtla.VSCtl_tqCkEfcMaxNotCtla
          dr_VSCtl_stCtl_tqWhlPotMin: data-element=R_VSCtl_stCtl_tqWhlPotMin.VSCtl_stCtl_tqWhlPotMin
          dr_VSCtl_tqWhlMinSat: data-element=R_VSCtl_tqWhlMinSat.VSCtl_tqWhlMinSat
        30 x data send point:
          ds_VSCtl_noGearReqMax: data-element=P_VSCtl_noGearReqMax.VSCtl_noGearReqMax
          ds_VSCtl_bCtlEfc_tqCkEfcMin: data-element=P_VSCtl_bCtlEfc_tqCkEfcMin.VSCtl_bCtlEfc_tqCkEfcMin
          ds_VSCtl_bAcvTqWhlPTMinSat: data-element=P_VSCtl_bAcvTqWhlPTMinSat.VSCtl_bAcvTqWhlPTMinSat
          ds_VSCtl_stGearCtlReq: data-element=P_VSCtl_stGearCtlReq.VSCtl_stGearCtlReq
          ds_VSCtl_tqWhlPTMinReq: data-element=P_VSCtl_tqWhlPTMinReq.VSCtl_tqWhlPTMinReq
          ds_VSCtl_rAccPEngMax: data-element=P_VSCtl_rAccPEngMax.VSCtl_rAccPEngMax
          ds_VSCtl_tqEfcTarMin: data-element=P_VSCtl_tqEfcTarMin.VSCtl_tqEfcTarMin
          ds_VSCtl_stTqWhlPTCutOffReq: data-element=P_VSCtl_stTqWhlPTCutOffReq.VSCtl_stTqWhlPTCutOffReq
          ds_VSCtl_bCtlEfc_tqWhlPTMax: data-element=P_VSCtl_bCtlEfc_tqWhlPTMax.VSCtl_bCtlEfc_tqWhlPTMax
          ds_VSCtl_tqCkEfcMinReq: data-element=P_VSCtl_tqCkEfcMinReq.VSCtl_tqCkEfcMinReq
          ds_VSCtl_tqWhlPTPotMinReq: data-element=P_VSCtl_tqWhlPTPotMinReq.VSCtl_tqWhlPTPotMinReq
          ds_VSCtl_tqWhlPTMaxReq: data-element=P_VSCtl_tqWhlPTMaxReq.VSCtl_tqWhlPTMaxReq
          ds_VSCtl_bCtlEfc_tqCkEfcMax: data-element=P_VSCtl_bCtlEfc_tqCkEfcMax.VSCtl_bCtlEfc_tqCkEfcMax
          ds_VSCtl_tiCfmSupReq: data-element=P_VSCtl_tiCfmSupReq.VSCtl_tiCfmSupReq
          ds_VSCtl_rAccPPTMin: data-element=P_VSCtl_rAccPPTMin.VSCtl_rAccPPTMin
          ds_VSCtl_bCtlEfc_tqWhlPTMin: data-element=P_VSCtl_bCtlEfc_tqWhlPTMin.VSCtl_bCtlEfc_tqWhlPTMin
          ds_VSCtl_noGearReqMin: data-element=P_VSCtl_noGearReqMin.VSCtl_noGearReqMin
          ds_VSCtl_rAccPEngMin: data-element=P_VSCtl_rAccPEngMin.VSCtl_rAccPEngMin
          ds_VSCtl_tqCkEfcMaxReq: data-element=P_VSCtl_tqCkEfcMaxReq.VSCtl_tqCkEfcMaxReq
          ds_VSCtl_tqEfcTarMax: data-element=P_VSCtl_tqEfcTarMax.VSCtl_tqEfcTarMax
          ds_VSCtl_tqWhlPTPotReq: data-element=P_VSCtl_tqWhlPTPotReq.VSCtl_tqWhlPTPotReq
          ds_VSCtl_stCtl_noGear: data-element=P_VSCtl_stCtl_noGear.VSCtl_stCtl_noGear
          ds_VSCtl_rAccPPTMax: data-element=P_VSCtl_rAccPPTMax.VSCtl_rAccPPTMax
          ds_VSCtl_rAccPTraMin: data-element=P_VSCtl_rAccPTraMin.VSCtl_rAccPTraMin
          ds_VSCtl_tqWhlPTPotMaxReq: data-element=P_VSCtl_tqWhlPTPotMaxReq.VSCtl_tqWhlPTPotMaxReq
          ds_VSCtl_bInhRecup: data-element=P_VSCtl_bInhRecup.VSCtl_bInhRecup
          ds_VSCtl_tiCfmSdwnReq: data-element=P_VSCtl_tiCfmSdwnReq.VSCtl_tiCfmSdwnReq
          ds_VSCtl_tqWhlPTMinSat: data-element=P_VSCtl_tqWhlPTMinSat.VSCtl_tqWhlPTMinSat
          ds_VSCtl_stTqWhlPTPotCtlReq: data-element=P_VSCtl_stTqWhlPTPotCtlReq.VSCtl_stTqWhlPTPotCtlReq
          ds_VSCtl_rAccPTraMax: data-element=P_VSCtl_rAccPTraMax.VSCtl_rAccPTraMax
        sync call ssp_FRM_bDeacVSCtlGearCtl: operation=R_FRM_bDeacVSCtlGearCtl.GetFunctionPermission
        sync call ssp_GetTimer_1ms_U32: operation=R_VSSp_GetTimer_1ms_U32.GetTimer_1ms_U32
      RE_VSSp_003_TEV: read-variable=[VSCtl_stTqPTMaxCtl_pt1, VSCtl_bCtlEfc_tqWhlPT_pt2, VSCtl_bCtlEfc_tqWhlPT_pt1, VSCtl_stTqPTMinCtl_pt1, VSCtl_stTqPTMinCtl_pt2, VSCtl_stTqPTMaxCtl_pt2]  # RE_01552_10_02851_40ms
        data receive point DRP_R_Ext_bCtlCmdPTTqCf_Ext_bCtlCmdPTTqCf: data-element=R_Ext_bCtlCmdPTTqCf.Ext_bCtlCmdPTTqCf
        data send point ds_VSCtl_stTqPTMaxCtl: data-element=P_VSCtl_stTqPTMaxCtl.VSCtl_stTqPTMaxCtl
        data send point ds_VSCtl_stTqPTMinCtl: data-element=P_VSCtl_stTqPTMinCtl.VSCtl_stTqPTMinCtl
        data send point ds_VSCtl_bCtlEfc_tqWhlPt: data-element=P_VSCtl_bCtlEfc_tqWhlPt.VSCtl_bCtlEfc_tqWhlPt
        sync call ssp_GetTimer_1ms_U32: operation=R_VSSp_GetTimer_1ms_U32.GetTimer_1ms_U32
      RE_VSSp_004_MSE: written-variable=[VSCtl_bCtlEfc_tqWhlPT_pt1, VSCtl_stTqPTMaxCtl_pt2, VSCtl_stTqPTMinCtl_pt1, VSCtl_bCtlEfc_tqWhlPT_pt2, VSCtl_stTqPTMaxCtl_pt1, VSCtl_stTqPTMinCtl_pt2]  # RE_01552_10_02851_HotReset_init
        33 x data send point:
          ds_VSCtl_stTqWhlPTCutOffReq: data-element=P_VSCtl_stTqWhlPTCutOffReq.VSCtl_stTqWhlPTCutOffReq
          ds_VSCtl_stCtl_noGear: data-element=P_VSCtl_stCtl_noGear.VSCtl_stCtl_noGear
          ds_VSCtl_bCtlEfc_tqCkEfcMax: data-element=P_VSCtl_bCtlEfc_tqCkEfcMax.VSCtl_bCtlEfc_tqCkEfcMax
          ds_VSCtl_tqWhlPTPotReq: data-element=P_VSCtl_tqWhlPTPotReq.VSCtl_tqWhlPTPotReq
          ds_VSCtl_rAccPPTMin: data-element=P_VSCtl_rAccPPTMin.VSCtl_rAccPPTMin
          ds_VSCtl_stTqWhlPTPotCtlReq: data-element=P_VSCtl_stTqWhlPTPotCtlReq.VSCtl_stTqWhlPTPotCtlReq
          ds_VSCtl_tqWhlPTMinReq: data-element=P_VSCtl_tqWhlPTMinReq.VSCtl_tqWhlPTMinReq
          ds_VSCtl_tqWhlPTPotMaxReq: data-element=P_VSCtl_tqWhlPTPotMaxReq.VSCtl_tqWhlPTPotMaxReq
          ds_VSCtl_rAccPEngMin: data-element=P_VSCtl_rAccPEngMin.VSCtl_rAccPEngMin
          ds_VSCtl_stGearCtlReq: data-element=P_VSCtl_stGearCtlReq.VSCtl_stGearCtlReq
          ds_VSCtl_rAccPPTMax: data-element=P_VSCtl_rAccPPTMax.VSCtl_rAccPPTMax
          ds_VSCtl_bCtlEfc_tqWhlPt: data-element=P_VSCtl_bCtlEfc_tqWhlPt.VSCtl_bCtlEfc_tqWhlPt
          ds_VSCtl_bCtlEfc_tqWhlPTMin: data-element=P_VSCtl_bCtlEfc_tqWhlPTMin.VSCtl_bCtlEfc_tqWhlPTMin
          ds_VSCtl_rAccPTraMin: data-element=P_VSCtl_rAccPTraMin.VSCtl_rAccPTraMin
          ds_VSCtl_tqCkEfcMinReq: data-element=P_VSCtl_tqCkEfcMinReq.VSCtl_tqCkEfcMinReq
          ds_VSCtl_tqEfcTarMin: data-element=P_VSCtl_tqEfcTarMin.VSCtl_tqEfcTarMin
          ds_VSCtl_stTqPTMaxCtl: data-element=P_VSCtl_stTqPTMaxCtl.VSCtl_stTqPTMaxCtl
          ds_VSCtl_tqWhlPTPotMinReq: data-element=P_VSCtl_tqWhlPTPotMinReq.VSCtl_tqWhlPTPotMinReq
          ds_VSCtl_bCtlEfc_tqWhlPTMax: data-element=P_VSCtl_bCtlEfc_tqWhlPTMax.VSCtl_bCtlEfc_tqWhlPTMax
          ds_VSCtl_noGearReqMin: data-element=P_VSCtl_noGearReqMin.VSCtl_noGearReqMin
          ds_VSCtl_tqWhlPTMinSat: data-element=P_VSCtl_tqWhlPTMinSat.VSCtl_tqWhlPTMinSat
          ds_VSCtl_tiCfmSupReq: data-element=P_VSCtl_tiCfmSupReq.VSCtl_tiCfmSupReq
          ds_VSCtl_stTqPTMinCtl: data-element=P_VSCtl_stTqPTMinCtl.VSCtl_stTqPTMinCtl
          ds_VSCtl_bAcvTqWhlPTMinSat: data-element=P_VSCtl_bAcvTqWhlPTMinSat.VSCtl_bAcvTqWhlPTMinSat
          ds_VSCtl_tqWhlPTMaxReq: data-element=P_VSCtl_tqWhlPTMaxReq.VSCtl_tqWhlPTMaxReq
          ds_VSCtl_rAccPEngMax: data-element=P_VSCtl_rAccPEngMax.VSCtl_rAccPEngMax
          ds_VSCtl_rAccPTraMax: data-element=P_VSCtl_rAccPTraMax.VSCtl_rAccPTraMax
          ds_VSCtl_tqEfcTarMax: data-element=P_VSCtl_tqEfcTarMax.VSCtl_tqEfcTarMax
          ds_VSCtl_noGearReqMax: data-element=P_VSCtl_noGearReqMax.VSCtl_noGearReqMax
          ds_VSCtl_bCtlEfc_tqCkEfcMin: data-element=P_VSCtl_bCtlEfc_tqCkEfcMin.VSCtl_bCtlEfc_tqCkEfcMin
          ds_VSCtl_tiCfmSdwnReq: data-element=P_VSCtl_tiCfmSdwnReq.VSCtl_tiCfmSdwnReq
          ds_VSCtl_bInhRecup: data-element=P_VSCtl_bInhRecup.VSCtl_bInhRecup
          ds_VSCtl_tqCkEfcMaxReq: data-element=P_VSCtl_tqCkEfcMaxReq.VSCtl_tqCkEfcMaxReq
        sync call ssp_GetTimer_1ms_U32: operation=R_VSSp_GetTimer_1ms_U32.GetTimer_1ms_U32
      RE_VSSp_001_MSE: written-variable=[VSCtl_bCtlEfc_tqWhlPT_pt1, VSCtl_stTqPTMaxCtl_pt1, VSCtl_stTqPTMaxCtl_pt2, VSCtl_bCtlEfc_tqWhlPT_pt2, VSCtl_stTqPTMinCtl_pt1, VSCtl_stTqPTMinCtl_pt2]  # RE_01552_10_02851_init
        33 x data send point:
          ds_VSCtl_stCtl_noGear: data-element=P_VSCtl_stCtl_noGear.VSCtl_stCtl_noGear
          ds_VSCtl_tqWhlPTPotMaxReq: data-element=P_VSCtl_tqWhlPTPotMaxReq.VSCtl_tqWhlPTPotMaxReq
          ds_VSCtl_rAccPTraMax: data-element=P_VSCtl_rAccPTraMax.VSCtl_rAccPTraMax
          ds_VSCtl_rAccPEngMax: data-element=P_VSCtl_rAccPEngMax.VSCtl_rAccPEngMax
          ds_VSCtl_stTqPTMaxCtl: data-element=P_VSCtl_stTqPTMaxCtl.VSCtl_stTqPTMaxCtl
          ds_VSCtl_bCtlEfc_tqWhlPTMax: data-element=P_VSCtl_bCtlEfc_tqWhlPTMax.VSCtl_bCtlEfc_tqWhlPTMax
          ds_VSCtl_tqWhlPTMaxReq: data-element=P_VSCtl_tqWhlPTMaxReq.VSCtl_tqWhlPTMaxReq
          ds_VSCtl_tqWhlPTPotReq: data-element=P_VSCtl_tqWhlPTPotReq.VSCtl_tqWhlPTPotReq
          ds_VSCtl_tqEfcTarMax: data-element=P_VSCtl_tqEfcTarMax.VSCtl_tqEfcTarMax
          ds_VSCtl_tqCkEfcMaxReq: data-element=P_VSCtl_tqCkEfcMaxReq.VSCtl_tqCkEfcMaxReq
          ds_VSCtl_tqEfcTarMin: data-element=P_VSCtl_tqEfcTarMin.VSCtl_tqEfcTarMin
          ds_VSCtl_rAccPPTMax: data-element=P_VSCtl_rAccPPTMax.VSCtl_rAccPPTMax
          ds_VSCtl_tqCkEfcMinReq: data-element=P_VSCtl_tqCkEfcMinReq.VSCtl_tqCkEfcMinReq
          ds_VSCtl_stTqPTMinCtl: data-element=P_VSCtl_stTqPTMinCtl.VSCtl_stTqPTMinCtl
          ds_VSCtl_rAccPEngMin: data-element=P_VSCtl_rAccPEngMin.VSCtl_rAccPEngMin
          ds_VSCtl_rAccPTraMin: data-element=P_VSCtl_rAccPTraMin.VSCtl_rAccPTraMin
          ds_VSCtl_tiCfmSupReq: data-element=P_VSCtl_tiCfmSupReq.VSCtl_tiCfmSupReq
          ds_VSCtl_tqWhlPTMinReq: data-element=P_VSCtl_tqWhlPTMinReq.VSCtl_tqWhlPTMinReq
          ds_VSCtl_bInhRecup: data-element=P_VSCtl_bInhRecup.VSCtl_bInhRecup
          ds_VSCtl_stGearCtlReq: data-element=P_VSCtl_stGearCtlReq.VSCtl_stGearCtlReq
          ds_VSCtl_bCtlEfc_tqWhlPTMin: data-element=P_VSCtl_bCtlEfc_tqWhlPTMin.VSCtl_bCtlEfc_tqWhlPTMin
          ds_VSCtl_stTqWhlPTPotCtlReq: data-element=P_VSCtl_stTqWhlPTPotCtlReq.VSCtl_stTqWhlPTPotCtlReq
          ds_VSCtl_rAccPPTMin: data-element=P_VSCtl_rAccPPTMin.VSCtl_rAccPPTMin
          ds_VSCtl_bCtlEfc_tqCkEfcMax: data-element=P_VSCtl_bCtlEfc_tqCkEfcMax.VSCtl_bCtlEfc_tqCkEfcMax
          ds_VSCtl_bCtlEfc_tqWhlPt: data-element=P_VSCtl_bCtlEfc_tqWhlPt.VSCtl_bCtlEfc_tqWhlPt
          ds_VSCtl_noGearReqMax: data-element=P_VSCtl_noGearReqMax.VSCtl_noGearReqMax
          ds_VSCtl_bCtlEfc_tqCkEfcMin: data-element=P_VSCtl_bCtlEfc_tqCkEfcMin.VSCtl_bCtlEfc_tqCkEfcMin
          ds_VSCtl_noGearReqMin: data-element=P_VSCtl_noGearReqMin.VSCtl_noGearReqMin
          ds_VSCtl_bAcvTqWhlPTMinSat: data-element=P_VSCtl_bAcvTqWhlPTMinSat.VSCtl_bAcvTqWhlPTMinSat
          ds_VSCtl_tiCfmSdwnReq: data-element=P_VSCtl_tiCfmSdwnReq.VSCtl_tiCfmSdwnReq
          ds_VSCtl_stTqWhlPTCutOffReq: data-element=P_VSCtl_stTqWhlPTCutOffReq.VSCtl_stTqWhlPTCutOffReq
          ds_VSCtl_tqWhlPTMinSat: data-element=P_VSCtl_tqWhlPTMinSat.VSCtl_tqWhlPTMinSat
          ds_VSCtl_tqWhlPTPotMinReq: data-element=P_VSCtl_tqWhlPTPotMinReq.VSCtl_tqWhlPTPotMinReq
        sync call ssp_GetTimer_1ms_U32: operation=R_VSSp_GetTimer_1ms_U32.GetTimer_1ms_U32
  swc implementation Imp_VSSp: programming-language=C, behavior=IB_VSSp
    code-descriptors:
      code CodeDescriptor: type=SRC
        13 x xfile:
          VSSP_Control_Wheel_Gmp1_Sl_c: url=VSSP_Control_Wheel_Gmp1_Sl.c
          VSSP_Potential_Gmp_Sl_c: url=VSSP_Potential_Gmp_Sl.c
          VSSp_h: url=VSSp.h
          VSSP_Control_Wheel_Gmp2_Sl_c: url=VSSP_Control_Wheel_Gmp2_Sl.c
          VSSP_Position_Pedale_Sl_c: url=VSSP_Position_Pedale_Sl.c
          VSSP_Det_Gearbox_Speed_Sl_c: url=VSSP_Det_Gearbox_Speed_Sl.c
          VSSP_Torque_Control_Gmp1_Sf_c: url=VSSP_Torque_Control_Gmp1_Sf.c
          VSSP_Det_Gearbox_Order_Sl_c: url=VSSP_Det_Gearbox_Order_Sl.c
          VSSP_Det_Gearbox_Pedal_Sf_c: url=VSSP_Det_Gearbox_Pedal_Sf.c
          VSSp_MemMap_h: url=VSSp_MemMap.h
          VSSP_Torque_Control_Gmp2_Sf_c: url=VSSP_Torque_Control_Gmp2_Sf.c
          VSSp_c: url=VSSp.c
          VSSP_Effec_Process_Xvv_c: url=VSSP_Effec_Process_Xvv.c
package /Components/SWC_VSSp/VSSp_IRVDatatypes
  boolean type DT_VSCtl_bCtlEfc_tqWhlPT_pt1: base-type=boolean
  boolean type DT_VSCtl_bCtlEfc_tqWhlPT_pt2: base-type=boolean
  4 x integer type, all with base-type=uint8, lower-limit=0, upper-limit=255:
    DT_VSCtl_stTqPTMaxCtl_pt1
    DT_VSCtl_stTqPTMaxCtl_pt2
    DT_VSCtl_stTqPTMinCtl_pt1
    DT_VSCtl_stTqPTMinCtl_pt2
